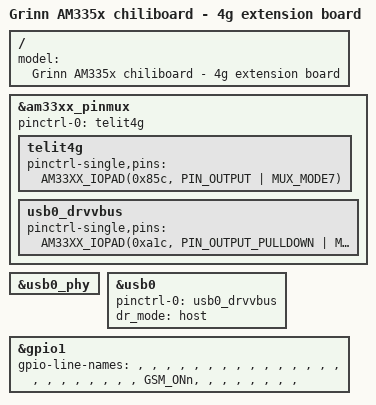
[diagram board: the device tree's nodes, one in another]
/*
 * Copyright 2017 Grinn
 *
 * Author: Michal Oleszczyk <m.oleszczyk@grinn-global.com>
 *
 * This file is dual-licensed: you can use it either under the terms
 * of the GPL or the X11 license, at your option. Note that this dual
 * licensing only applies to this file, and not this project as a
 * whole.
 *
 *  a) This file is free software; you can redistribute it and/or
 *     modify it under the terms of the GNU General Public License
 *     version 2 as published by the Free Software Foundation.
 *
 *     This file is distributed in the hope that it will be useful
 *     but WITHOUT ANY WARRANTY; without even the implied warranty of
 *     MERCHANTABILITY or FITNESS FOR A PARTICULAR PURPOSE.  See the
 *     GNU General Public License for more details.
 *
 * Or, alternatively
 *
 *  b) Permission is hereby granted, free of charge, to any person
 *     obtaining a copy of this software and associated documentation
 *     files (the "Software"), to deal in the Software without
 *     restriction, including without limitation the rights to use
 *     copy, modify, merge, publish, distribute, sublicense, and/or
 *     sell copies of the Software, and to permit persons to whom the
 *     Software is furnished to do so, subject to the following
 *     conditions:
 *
 *     The above copyright notice and this permission notice shall be
 *     included in all copies or substantial portions of the Software.
 *
 *     THE SOFTWARE IS PROVIDED , WITHOUT WARRANTY OF ANY KIND
 *     EXPRESS OR IMPLIED, INCLUDING BUT NOT LIMITED TO THE WARRANTIES
 *     OF MERCHANTABILITY, FITNESS FOR A PARTICULAR PURPOSE AND
 *     NONINFRINGEMENT. IN NO EVENT SHALL THE AUTHORS OR COPYRIGHT
 *     HOLDERS BE LIABLE FOR ANY CLAIM, DAMAGES OR OTHER LIABILITY
 *     WHETHER IN AN ACTION OF CONTRACT, TORT OR OTHERWISE, ARISING
 *     FROM, OUT OF OR IN CONNECTION WITH THE SOFTWARE OR THE USE OR
 *     OTHER DEALINGS IN THE SOFTWARE.
 */

#include "am335x-chiliboard.dts"

/ {
	model = "Grinn AM335x chiliboard - 4g extension board";
};

&am33xx_pinmux {
	pinctrl-names = "default";
	pinctrl-0 = <&telit4g>;

	telit4g: telit4g {
		pinctrl-single,pins = <
			AM33XX_IOPAD(0x85c, PIN_OUTPUT | MUX_MODE7) /* (T15) gpmc_a7.gpio1[23] */
		>;
	};

	usb0_drvvbus: usb0_drvvbus {
		pinctrl-single,pins = <
			AM33XX_IOPAD(0xa1c, PIN_OUTPUT_PULLDOWN | MUX_MODE0) /* usb0_drvvbus.usb0_drvvbus */
		>;
	};
};

&usb0_phy {
	status = "okay";
};

&usb0 {
	pinctrl-names = "default";
	pinctrl-0 = <&usb0_drvvbus>;

	status = "okay";
	dr_mode = "host";
};

&gpio1 {
	gpio-line-names = "", "", "", "", "", "", "", "",
		"", "", "", "", "", "", "", "",
		"", "", "", "", "", "", "", "GSM_ONn",
		"", "", "", "", "", "", "", "";
};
